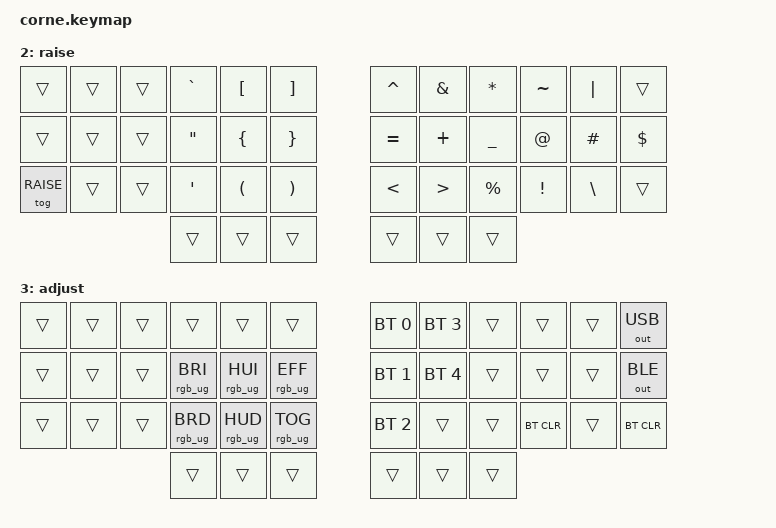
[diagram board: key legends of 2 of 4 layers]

#include <behaviors.dtsi>
#include <dt-bindings/zmk/keys.h>
#include <dt-bindings/zmk/bt.h>
#include <dt-bindings/zmk/outputs.h>
#include <dt-bindings/zmk/rgb.h>
#include <dt-bindings/zmk/modifiers.h>

#define BASE 0
#define LOWER 1
#define RAISE 2
#define ADJUST 3

// Home row mods: one shared hold-tap behavior, four keys per half
#define HRML(k1,k2,k3,k4) &ht LSHFT k1 &ht LALT k2 &ht LCTRL k3 &ht LGUI k4
#define HRMR(k1,k2,k3,k4) &ht RGUI k1 &ht RCTRL k2 &ht RALT k3 &ht RSHFT k4

/ {
    behaviors {
        ht: hold_tap {
            compatible = "zmk,behavior-hold-tap";
            #binding-cells = <2>;
            flavor = "tap-preferred";
            tapping-term-ms = <220>;
            quick-tap-ms = <150>;
            global-quick-tap;
            bindings = <&kp>, <&kp>;
        };

        lower_tap_hold: lower_tap_hold {
            compatible = "zmk,behavior-hold-tap";
            #binding-cells = <2>;
            flavor = "hold-preferred";
            tapping-term-ms = <200>;
            bindings = <&mo>, <&kp>;
        };

        altgr_tap_hold: altgr_tap_hold {
            compatible = "zmk,behavior-hold-tap";
            #binding-cells = <2>;
            flavor = "hold-preferred";
            tapping-term-ms = <200>;
            bindings = <&kp>, <&kp>;
        };

        // comma, shift+comma = ; (norwegian layout on US host)
        comma_semi: comma_semi {
            compatible = "zmk,behavior-mod-morph";
            #binding-cells = <0>;
            bindings = <&kp COMMA>, <&kp SEMI>;
            mods = <(MOD_LSFT|MOD_RSFT)>;
        };

        // dot, shift+dot = : (shift is masked, COLON adds its own)
        dot_colon: dot_colon {
            compatible = "zmk,behavior-mod-morph";
            #binding-cells = <0>;
            bindings = <&kp DOT>, <&kp COLON>;
            mods = <(MOD_LSFT|MOD_RSFT)>;
        };
    };

    conditional_layers {
        compatible = "zmk,conditional-layers";

        lower_raise_adjust_default {
            if-layers = <LOWER RAISE>;
            then-layer = <ADJUST>;
        };
    };

    keymap {
        compatible = "zmk,keymap";

        base {
                bindings = <
                    //╭──────────┬──────────┬──────────┬──────────┬──────────┬──────────╮   ╭──────────┬──────────┬──────────┬──────────┬──────────┬──────────╮
                    //│  none    │  Q       │  W       │  F       │  P       │  B       │   │  J       │  L       │  U       │  Y       │  '       │  none    │
                    &none       &kp Q       &kp W       &kp F       &kp P       &kp B         &kp J       &kp L       &kp U       &kp Y  &kp SQT       &none
                    //├──────────┼──────────┼──────────┼──────────┼──────────┼──────────┤   ├──────────┼──────────┼──────────┼──────────┼──────────┼──────────┤
                    //│  none    │  LSHFT A │  LALT R  │  LCTRL S │  LGUI T  │  G       │   │  M       │  RGUI N  │  RCTRL E │  RALT I  │  RSHFT O │  -       │
                    &none       HRML(A, R, S, T) &kp G         &kp M       HRMR(N, E, I, O) &kp MINUS
                    //├──────────┼──────────┼──────────┼──────────┼──────────┼──────────┤   ├──────────┼──────────┼──────────┼──────────┼──────────┼──────────┤
                    //│  none    │  Z       │  X       │  C       │  D       │  V       │   │  K       │  H       │   , ;    │  . :     │  FSLH    │  none    │
                    &none       &kp Z       &kp X       &kp C       &kp D       &kp V         &kp K       &kp H &comma_semi &dot_colon &kp FSLH    &none
                    //╰──────────┴──────────┴──────────┴──────────┴──────────┴──────────╯   ╰──────────┴──────────┴──────────┴──────────┴──────────┴──────────╯
                    //                                 ╭──────────┬──────────┬──────────╮   ╭──────────┬──────────┬──────────╮
                    //                                 │  ESC     │ LOWER TAB│  SPACE   │   │  ENTER   │  RAISE   │ RALT BSPC│
                                                     &kp ESC     &lower_tap_hold LOWER TAB &kp SPACE     &kp RET   &mo RAISE   &altgr_tap_hold RALT BSPC
                    //                                 ╰──────────┴──────────┴──────────╯   ╰──────────┴──────────┴──────────╯
                >;
            };

        lower {
                bindings = <
                    //╭──────────┬──────────┬──────────┬──────────┬──────────┬──────────╮   ╭──────────┬──────────┬──────────┬──────────┬──────────┬──────────╮
                    //│  trans   │   FSLH   │    N7    │    N8    │    N9    │   BSLH   │   │   HOME   │  PG_DN   │  PG_UP   │   END    │  trans   │  trans   │
                    &trans      &kp FSLH    &kp N7      &kp N8      &kp N9      &kp BSLH      &kp HOME    &kp PG_DN   &kp PG_UP   &kp END     &trans      &trans
                    //├──────────┼──────────┼──────────┼──────────┼──────────┼──────────┤   ├──────────┼──────────┼──────────┼──────────┼──────────┼──────────┤
                    //│    N0    │ LSHFT -  │ LALT N4  │ LCTRL N5 │ LGUI N6  │  QMARK   │   │   LEFT   │RGUI DOWN │ RCTRL UP │RALT RGHT │  RSHFT   │  trans   │
                    &kp N0      HRML(MINUS, N4, N5, N6) &kp QMARK                          &kp LEFT    &ht RGUI DOWN &ht RCTRL UP &ht RALT RIGHT &kp RSHFT &trans
                    //├──────────┼──────────┼──────────┼──────────┼──────────┼──────────┤   ├──────────┼──────────┼──────────┼──────────┼──────────┼──────────┤
                    //│  trans   │   EXCL   │    N1    │    N2    │    N3    │   DOT    │   │   DEL    │  trans   │  trans   │  trans   │  trans   │  trans   │
                    &tog LOWER  &kp EXCL    &kp N1      &kp N2      &kp N3      &kp DOT       &kp DEL     &trans      &trans      &trans      &trans      &trans
                    //╰──────────┴──────────┴──────────┴──────────┴──────────┴──────────╯   ╰──────────┴──────────┴──────────┴──────────┴──────────┴──────────╯
                    //                                 ╭──────────┬──────────┬──────────╮   ╭──────────┬──────────┬──────────╮
                    //                                 │  trans   │  trans   │  trans   │   │  trans   │  trans   │  trans   │
                                                         &trans      &trans      &trans        &trans      &trans      &trans
                    //                                 ╰──────────┴──────────┴──────────╯   ╰──────────┴──────────┴──────────╯
                >;
            };

        raise {
                bindings = <
                    //╭──────────┬──────────┬──────────┬──────────┬──────────┬──────────╮   ╭──────────┬──────────┬──────────┬──────────┬──────────┬──────────╮
                    //│  trans   │  trans   │  trans   │  GRAVE   │   LBKT   │   RBKT   │   │  CARET   │   AMPS   │   STAR   │  TILDE   │   PIPE   │  trans   │
                    &trans      &trans      &trans      &kp GRAVE   &kp LBKT    &kp RBKT      &kp CARET   &kp AMPS    &kp STAR    &kp TILDE   &kp PIPE    &trans
                    //├──────────┼──────────┼──────────┼──────────┼──────────┼──────────┤   ├──────────┼──────────┼──────────┼──────────┼──────────┼──────────┤
                    //│  trans   │  trans   │  trans   │   DQT    │   LBRC   │   RBRC   │   │  EQUAL   │   PLUS   │  UNDER   │    AT    │   HASH   │   DLLR   │
                    &trans      &trans      &trans      &kp DQT     &kp LBRC    &kp RBRC      &kp EQUAL   &kp PLUS    &kp UNDER   &kp AT      &kp HASH    &kp DLLR
                    //├──────────┼──────────┼──────────┼──────────┼──────────┼──────────┤   ├──────────┼──────────┼──────────┼──────────┼──────────┼──────────┤
                    //│  trans   │  trans   │  trans   │   SQT    │   LPAR   │   RPAR   │   │    LT    │    GT    │  PRCNT   │   EXCL   │   BSLH   │  trans   │
                    &tog RAISE  &trans      &trans      &kp SQT     &kp LPAR    &kp RPAR      &kp LT      &kp GT      &kp PRCNT   &kp EXCL    &kp BSLH    &trans
                    //╰──────────┴──────────┴──────────┴──────────┴──────────┴──────────╯   ╰──────────┴──────────┴──────────┴──────────┴──────────┴──────────╯
                    //                                 ╭──────────┬──────────┬──────────╮   ╭──────────┬──────────┬──────────╮
                    //                                 │  trans   │  trans   │  trans   │   │  trans   │  trans   │  trans   │
                                                         &trans      &trans     &trans         &trans     &trans     &trans
                    //                                 ╰──────────┴──────────┴──────────╯   ╰──────────┴──────────┴──────────╯
                >;
            };

        adjust {
                bindings = <
                    //╭──────────┬──────────┬──────────┬──────────┬──────────┬──────────╮   ╭──────────┬──────────┬──────────┬──────────┬──────────┬──────────╮
                    //│  trans   │   trans  │  trans   │  trans   │  trans   │  trans   │   │  BT_SEL 0│  BT_SEL 3│  trans   │  trans   │  trans   │  OUT_USB │
                        &trans      &trans &trans       &trans      &trans     &trans     &bt BT_SEL 0 &bt BT_SEL 3 &trans    &trans     &trans &out OUT_USB
                    //├──────────┼──────────┼──────────┼──────────┼──────────┼──────────┤   ├──────────┼──────────┼──────────┼──────────┼──────────┼──────────┤
                    //│  trans   │  trans   │  trans   │  RGB_BRI │  RGB_HUI │  RGB_EFF │   │  BT_SEL 1│  BT_SEL 4│  trans   │  trans   │  trans   │  OUT_BLE │
                     &trans &trans &trans &rgb_ug RGB_BRI &rgb_ug RGB_HUI &rgb_ug RGB_EFF  &bt BT_SEL 1 &bt BT_SEL 4 &trans    &trans     &trans &out OUT_BLE
                    //├──────────┼──────────┼──────────┼──────────┼──────────┼──────────┤   ├──────────┼──────────┼──────────┼──────────┼──────────┼──────────┤
                    //│  trans   │  trans   │  trans   │  RGB_BRD │  RGB_HUD │  RGB_TOG │   │  BT_SEL 2│  trans   │  trans   │  BT CLR  │  trans   │  BT_CLR  │
                     &trans &trans &trans &rgb_ug RGB_BRD &rgb_ug RGB_HUD &rgb_ug RGB_TOG  &bt BT_SEL 2  &trans     &trans     &bt BT_CLR &trans  &bt BT_CLR
                    //╰──────────┴──────────┴──────────┴──────────┴──────────┴──────────╯   ╰──────────┴──────────┴──────────┴──────────┴──────────┴──────────╯
                    //                                 ╭──────────┬──────────┬──────────╮   ╭──────────┬──────────┬──────────╮
                    //                                 │  trans   │  trans   │  trans   │   │  trans   │  trans   │  trans   │
                                                     &trans      &trans      &trans        &trans      &trans      &trans
                    //                                 ╰──────────┴──────────┴──────────╯   ╰──────────┴──────────┴──────────╯
                >;
            };
    };
};

&led_strip {
    chain-length = <27>;
};
